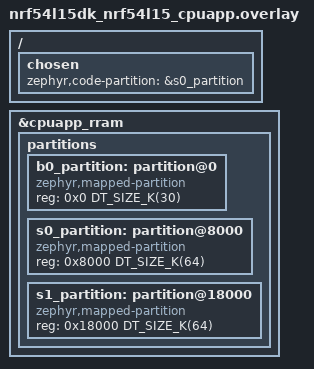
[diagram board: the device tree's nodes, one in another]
/*
 * Copyright (c) 2026 Nordic Semiconductor ASA
 *
 * SPDX-License-Identifier: LicenseRef-Nordic-5-Clause
 */

&cpuapp_rram {
	/delete-node/ partitions;

	partitions {
		ranges;
		#address-cells = <1>;
		#size-cells = <1>;

		b0_partition: partition@0 {
			compatible = "zephyr,mapped-partition";
			reg = <0x0 DT_SIZE_K(30)>;
		};

		s0_partition: partition@8000 {
			compatible = "zephyr,mapped-partition";
			reg = <0x8000 DT_SIZE_K(64)>;
		};

		s1_partition: partition@18000 {
			compatible = "zephyr,mapped-partition";
			reg = <0x18000 DT_SIZE_K(64)>;
		};
	};
};

/ {
	chosen {
		zephyr,code-partition = &s0_partition;
	};
};
